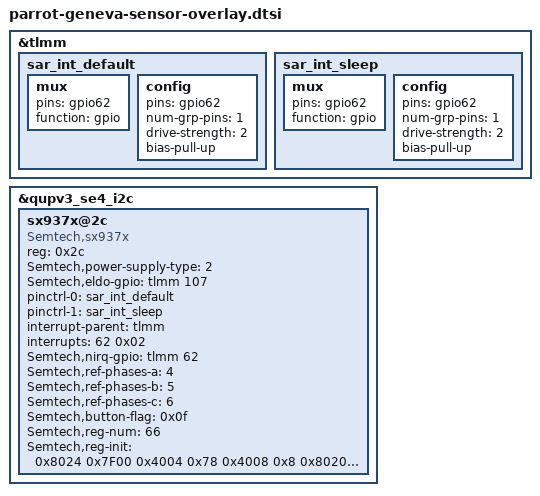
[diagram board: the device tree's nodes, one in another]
/* Copyright (c) 2021, The Linux Foundation. All rights reserved.
 *
 * This program is free software; you can redistribute it and/or modify
 * it under the terms of the GNU General Public License version 2 and
 * only version 2 as published by the Free Software Foundation.
 *
 * This program is distributed in the hope that it will be useful,
 * but WITHOUT ANY WARRANTY; without even the implied warranty of
 * MERCHANTABILITY or FITNESS FOR A PARTICULAR PURPOSE.  See the
 * GNU General Public License for more details.
 */

&tlmm {
	sar_int_default: sar_int_default {
			mux {
				pins = "gpio62";
				function =  "gpio";
			};
			config {
				pins = "gpio62";
				num-grp-pins = <1>;
				drive-strength = <2>;
				bias-pull-up;
			};
	};

	sar_int_sleep: sar_int_sleep {
			mux {
				pins = "gpio62";
				function =  "gpio";
			};
			config {
				pins = "gpio62";
				num-grp-pins = <1>;
				drive-strength = <2>;
				bias-pull-up;
			};
	};
};

&qupv3_se4_i2c {
	status = "ok";
	sx937x@2c { /* SAR sensor */
		compatible = "Semtech,sx937x";
		reg = <0x2c>;
		Semtech,power-supply-type = <2>;
		Semtech,eldo-gpio = <&tlmm 107 0x02>;
		pinctrl-names = "default","sleep";
		pinctrl-0 = <&sar_int_default>;
		pinctrl-1 = <&sar_int_sleep>;
		interrupt-parent = <&tlmm>;
		interrupts = <62 0x02>;
		interrupt-names = "sx937x_irq";
		Semtech,nirq-gpio= <&tlmm 62 0x02>;
		/*use PH4/5/6 as the reference sensor
		set it to 0xff if the ref-phases-x is not used*/
		Semtech,ref-phases-a = <4>;
		Semtech,ref-phases-b = <5>;
		Semtech,ref-phases-c = <6>;
		Semtech,button-flag = <0x0f>;
		Semtech,reg-num = <66>;
		Semtech,reg-init = <
			0x8024 0x7F00 		/*PHEN, Disable all Phases*/
			0x4004 0x78 		/*irq mask*/
			0x4008 0x8
			0x8020 0x32

			0x8028 0x85E 		/*AFE_PARAM_PH0*/
			0x8034 0x85E 		/*AFE_PARAM_PH1*/
			0x8040 0x85E 		/*AFE_PARAM_PH2*/
			0x804C 0x85E    	/*AFE_PARAM_PH3*/
			0x8058 0x85E 		/*AFE_PARAM_PH4*/
			0x8064 0x85E 		/*AFE_PARAM_PH5*/
			0x8070 0x85E 		/*AFE_PARAM_PH6*/
			0x807C 0x85E    	/*AFE_PARAM_PH7*/

			/*set CS3 to hiz, because it used as IRQ pin*/
			0x8030 0xFFF9FD 	/*REG_AFEPH_PH0, CS4, ANT1, Bottom*/
			0x803C 0xFFF97F 	/*REG_AFEPH_PH1, CS7, ANT2, Top Right*/
			0x8048 0xFEF9FF 	/*REG_AFEPH_PH2, CS0, ANT3, Top Left*/
			0x8054 0xBFF9FF 	/*REG_AFEPH_PH3, CS5, ANT4, Top Right side*/
			0x8060 0xFFF9EF 	/*REG_AFEPH_PH4, CS6, ANT1_REF, Bottom*/
			0x806C 0xFFD9FF 	/*REG_AFEPH_PH5, CS2, ANT2_REF, Top Right*/
			0x8078 0xF7F9FF 	/*REG_AFEPH_PH6, CS1, ANT3_REF, Top Left*/
			0x8084 0xFFFFFF 	/*REG_AFEPH_PH7, NOT USE*/

			/*prox1 5000	0x64*/
			/*prox2 10000	0x8D*/
			/*prox3 15000	0xAD*/
			/*prox4 20000	0xC8*/
			0x8098 0x8440		/*prox threshold ph0*/
			0x80B8 0x372D		/*prox threshold ph1*/
			0x80D8 0x5A31		/*prox threshold ph2*/
			0x80F8 0x8348		/*prox threshold ph3*/
			0x8118 0xC8		/*prox threshold ph4*/
			0x8138 0xC8		/*prox threshold ph5*/
			0x8158 0xC8		/*prox threshold ph6*/
			0x8178 0xC8       	/*prox threshold ph7*/

			0x80A0 0x202000E0
			0x80C0 0x252500E0
			0x80E0 0x202000E0
			0x8100 0x141400E0
			0x8120 0x1F1F00E0
			0x8140 0x0
			0x8160 0x0
			0x8180 0x0
			0x8188 0x14
			0x818C 0x15
			0x8190 0x6
			0x8194 0x0
			0x8090 0x2AD67000
			0x80B0 0x2AD67000
			0x80D0 0x2AD67000
			0x80F0 0x2AD67000
			0x8110 0x2AD67000
			0x8130 0x2AD67000
			0x8150 0x2AD66000
			0x8170 0x2AD66000
			0x8088 0x300000
			0x80A8 0x300000
			0x80C8 0x300000
			0x80E8 0x300000
			0x8108 0x300000
			0x8128 0x300000
			0x8148 0x300000
			0x8168 0x300000
			0x808C 0x60200018
			0x80AC 0x60200018
			0x80CC 0x60200018
			0x80EC 0x60200018
			0x810C 0x60200018
			0x812C 0x60200018
			0x814C 0x60200018
			0x816C 0x60200018
			0x4280 0xE
			0x8024 0x7F7F
		>;
		status = "ok";
	};
};
